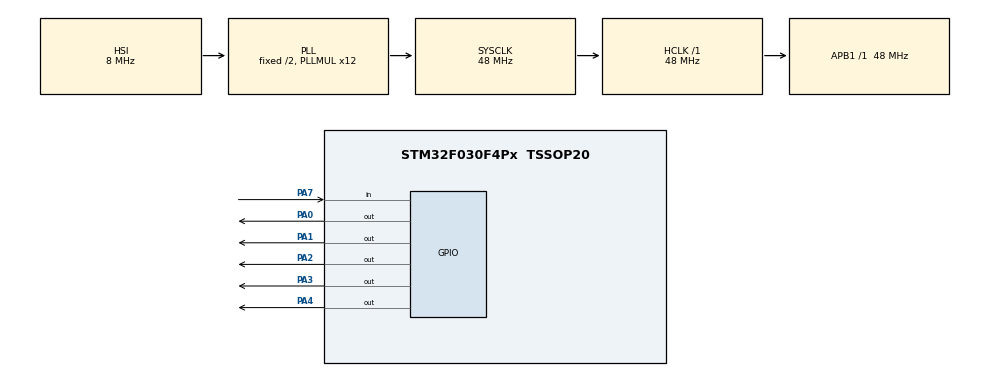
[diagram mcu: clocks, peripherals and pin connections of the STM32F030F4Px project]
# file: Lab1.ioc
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Mcu.Family=STM32F0
Mcu.Name=STM32F030F4Px
Mcu.Package=TSSOP20
PA0.Signal=GPIO_Output
PA1.Signal=GPIO_Output
PA13.Mode=Serial_Wire
PA13.Signal=SYS_SWDIO
PA14.Mode=Serial_Wire
PA14.Signal=SYS_SWCLK
PA2.Signal=GPIO_Output
PA3.Signal=GPIO_Output
PA4.Signal=GPIO_Output
PA7.Signal=GPIO_Input
ProjectManager.HeapSize=0x200
ProjectManager.StackSize=0x400
ProjectManager.TargetToolchain=STM32CubeIDE
RCC.AHBFreq_Value=48000000
RCC.APB1Freq_Value=48000000
RCC.APB1TimFreq_Value=48000000
RCC.HCLKFreq_Value=48000000
RCC.PLLMUL=RCC_PLL_MUL12
RCC.SYSCLKFreq_VALUE=48000000
RCC.SYSCLKSource=RCC_SYSCLKSOURCE_PLLCLK
board=custom

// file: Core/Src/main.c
/* USER CODE BEGIN Header */
/**
  ******************************************************************************
  * @file           : main.c
  * @brief          : Main program body
  ******************************************************************************
  * @attention
  *
  * Copyright (c) 2025 STMicroelectronics.
  * All rights reserved.
  *
  * This software is licensed under terms that can be found in the LICENSE file
  * in the root directory of this software component.
  * If no LICENSE file comes with this software, it is provided AS-IS.
  *
  ******************************************************************************
  */
/* USER CODE END Header */
#include "main.h"
#include "gpio.h"

/* USER CODE BEGIN PV */
int i = 0;
uint8_t dir = 0;
/* USER CODE END PV */

void SystemClock_Config(void);

int main(void)
{

  /* MCU Configuration--------------------------------------------------------*/

  /* Reset of all peripherals, Initializes the Flash interface and the Systick. */
  HAL_Init();

  /* Configure the system clock */
  SystemClock_Config();

  /* Initialize all configured peripherals */
  MX_GPIO_Init();

  /* Infinite loop */
  /* USER CODE BEGIN WHILE */
  while (1)
  {
/*
 //Task 1
	HAL_GPIO_WritePin(GPIOA, GPIO_PIN_0, GPIO_PIN_SET);
	HAL_Delay(50);

	HAL_GPIO_WritePin(GPIOA, GPIO_PIN_0, GPIO_PIN_RESET);
	HAL_Delay(50);
*/

/*
//Task 2

	GPIOA->BSRR |= 1;
	HAL_Delay(200);
	GPIOA->BSRR |= (1<<16);
	HAL_Delay(200);
*/

/*
//Task3
	GPIOA->BSRR = 1 << i;
	HAL_Delay(100);
	GPIOA->BSRR = 1 << (16 + i);

	i++;

	if (i == 5) i = 0;
*/
//Task4
	GPIOA->BSRR = 1 << i;
	HAL_Delay(100);
	GPIOA->BSRR = 1 << (16 + i);

	if(dir == 0){

		i++;

		if (i == 5){
			dir = 1;
		}

	}else{

		i--;

		if (i == 0){
			dir = 0;
		}

	}

    /* USER CODE END WHILE */

  }
}

void SystemClock_Config(void)
{
  RCC_OscInitTypeDef RCC_OscInitStruct = {0};
  RCC_ClkInitTypeDef RCC_ClkInitStruct = {0};

  /** Initializes the RCC Oscillators according to the specified parameters
  * in the RCC_OscInitTypeDef structure.
  */
  RCC_OscInitStruct.OscillatorType = RCC_OSCILLATORTYPE_HSI;
  RCC_OscInitStruct.HSIState = RCC_HSI_ON;
  RCC_OscInitStruct.HSICalibrationValue = RCC_HSICALIBRATION_DEFAULT;
  RCC_OscInitStruct.PLL.PLLState = RCC_PLL_ON;
  RCC_OscInitStruct.PLL.PLLSource = RCC_PLLSOURCE_HSI;
  RCC_OscInitStruct.PLL.PLLMUL = RCC_PLL_MUL12;
  RCC_OscInitStruct.PLL.PREDIV = RCC_PREDIV_DIV1;
  if (HAL_RCC_OscConfig(&RCC_OscInitStruct) != HAL_OK)
  {
    Error_Handler();
  }

  /** Initializes the CPU, AHB and APB buses clocks
  */
  RCC_ClkInitStruct.ClockType = RCC_CLOCKTYPE_HCLK|RCC_CLOCKTYPE_SYSCLK
                              |RCC_CLOCKTYPE_PCLK1;
  RCC_ClkInitStruct.SYSCLKSource = RCC_SYSCLKSOURCE_PLLCLK;
  RCC_ClkInitStruct.AHBCLKDivider = RCC_SYSCLK_DIV1;
  RCC_ClkInitStruct.APB1CLKDivider = RCC_HCLK_DIV1;

  if (HAL_RCC_ClockConfig(&RCC_ClkInitStruct, FLASH_LATENCY_1) != HAL_OK)
  {
    Error_Handler();
  }
}

void Error_Handler(void)
{
  __disable_irq();
  while (1)
  {
  }
}
